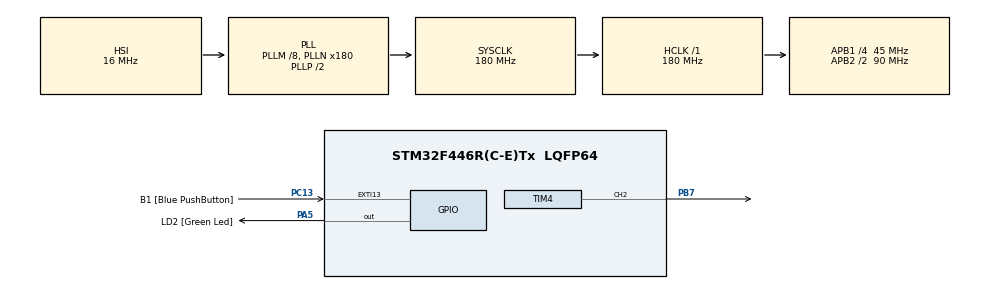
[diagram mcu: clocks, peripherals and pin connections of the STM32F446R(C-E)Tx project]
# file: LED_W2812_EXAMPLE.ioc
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Dma.Request0=TIM4_CH2
Dma.TIM4_CH2.0.Direction=DMA_MEMORY_TO_PERIPH
Dma.TIM4_CH2.0.FIFOMode=DMA_FIFOMODE_DISABLE
Dma.TIM4_CH2.0.Instance=DMA1_Stream3
Dma.TIM4_CH2.0.MemDataAlignment=DMA_MDATAALIGN_HALFWORD
Dma.TIM4_CH2.0.MemInc=DMA_MINC_ENABLE
Dma.TIM4_CH2.0.Mode=DMA_CIRCULAR
Dma.TIM4_CH2.0.PeriphDataAlignment=DMA_PDATAALIGN_HALFWORD
Dma.TIM4_CH2.0.PeriphInc=DMA_PINC_DISABLE
Dma.TIM4_CH2.0.Priority=DMA_PRIORITY_LOW
Mcu.Family=STM32F4
Mcu.Name=STM32F446R(C-E)Tx
Mcu.Package=LQFP64
NVIC.DMA1_Stream3_IRQn=true\:0\:0\:false\:false\:true\:false\:true\:true
NVIC.PriorityGroup=NVIC_PRIORITYGROUP_0
PA13.GPIO_Label=TMS
PA13.Signal=SYS_JTMS-SWDIO
PA14.GPIO_Label=TCK
PA14.Signal=SYS_JTCK-SWCLK
PA2.GPIO_Label=USART_TX
PA2.Signal=USART2_TX
PA3.GPIO_Label=USART_RX
PA3.Signal=USART2_RX
PA5.GPIO_Label=LD2 [Green Led]
PA5.Signal=GPIO_Output
PB3.GPIO_Label=SWO
PB3.Signal=SYS_JTDO-SWO
PB7.Signal=S_TIM4_CH2
PC13.GPIO_Label=B1 [Blue PushButton]
PC13.GPIO_ModeDefaultEXTI=GPIO_MODE_IT_FALLING
PC13.Signal=GPXTI13
PC14-OSC32_IN.Signal=RCC_OSC32_IN
PC15-OSC32_OUT.Signal=RCC_OSC32_OUT
PH0-OSC_IN.Signal=RCC_OSC_IN
PH1-OSC_OUT.Signal=RCC_OSC_OUT
ProjectManager.HeapSize=0x200
ProjectManager.StackSize=0x400
ProjectManager.TargetToolchain=STM32CubeIDE
RCC.AHBFreq_Value=180000000
RCC.APB1CLKDivider=RCC_HCLK_DIV4
RCC.APB1Freq_Value=45000000
RCC.APB1TimFreq_Value=90000000
RCC.APB2CLKDivider=RCC_HCLK_DIV2
RCC.APB2Freq_Value=90000000
RCC.APB2TimFreq_Value=180000000
RCC.CortexFreq_Value=180000000
RCC.FLatency-AdvancedSettings=FLASH_LATENCY_5
RCC.HCLKFreq_Value=180000000
RCC.HSE_VALUE=8000000
RCC.HSI_VALUE=16000000
RCC.LSE_VALUE=32768
RCC.PLLM=8
RCC.PLLN=180
RCC.SYSCLKFreq_VALUE=180000000
RCC.SYSCLKSource=RCC_SYSCLKSOURCE_PLLCLK
RCC.USBFreq_Value=180000000
RCC.VCOOutputFreq_Value=360000000
SH.S_TIM4_CH2.0=TIM4_CH2,PWM Generation2 CH2
TIM4.Channel-PWM\ Generation2\ CH2=TIM_CHANNEL_2
TIM4.OCFastMode_PWM-PWM\ Generation2\ CH2=TIM_OCFAST_DISABLE
TIM4.Period=112
VP_TIM4_VS_ClockSourceINT.Mode=Internal
board=NUCLEO-F446RE

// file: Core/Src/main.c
/* USER CODE BEGIN Header */
/**
 ******************************************************************************
 * @file           : main.c
 * @brief          : Main program body
 ******************************************************************************
 * @attention
 *
 * Copyright (c) 2022 STMicroelectronics.
 * All rights reserved.
 *
 * This software is licensed under terms that can be found in the LICENSE file
 * in the root directory of this software component.
 * If no LICENSE file comes with this software, it is provided AS-IS.
 *
 ******************************************************************************
 */
/* USER CODE END Header */
#include "main.h"
#include "dma.h"
#include "tim.h"
#include "gpio.h"

/* USER CODE BEGIN Includes */
#include "stdint.h"
#include "LED_W2812.h"
/* USER CODE END Includes */

/* USER CODE BEGIN PM */
#define LED_NUMBER 24
/* USER CODE END PM */

void SystemClock_Config(void);

/* USER CODE BEGIN 0 */
#define PUSH_BUTTON	HAL_GPIO_ReadPin(B1_GPIO_Port, B1_Pin)
/* USER CODE END 0 */

int MODE = 0;
int main(void)
{

	/* MCU Configuration--------------------------------------------------------*/

	/* Reset of all peripherals, Initializes the Flash interface and the Systick. */
	HAL_Init();

	/* Configure the system clock */
	SystemClock_Config();

	/* Initialize all configured peripherals */
	MX_GPIO_Init();
	MX_DMA_Init();
	MX_TIM4_Init();

	/* Infinite loop */
	/* USER CODE BEGIN WHILE */
	LED_init(&htim4, TIM_CHANNEL_2, LED_NUMBER);
	LED_setPeriode(10);
	LED_setColorAll(255, 255, 0, 0);

	while (1)
	{
		/* USER CODE END WHILE */

		/* USER CODE BEGIN 3 */
		LED_loop();

		HAL_GPIO_WritePin(LD2_GPIO_Port, LD2_Pin, PUSH_BUTTON);
		if (!PUSH_BUTTON)
		{
			while (!PUSH_BUTTON) HAL_Delay(10);
			MODE = (MODE + 1) % 6;
		}

		switch (MODE)
		{
			case 0: LED_setMode(LED_MODE_OFF); break;
			case 1: LED_setMode(LED_MODE_STATIC); break;
			case 2: LED_setMode(LED_MODE_BLINKING); break;
			case 3: LED_setMode(LED_MODE_BREATHING); break;
			case 4: LED_setMode(LED_MODE_RAINBOW1); break;
			case 5: LED_setMode(LED_MODE_RAINBOW1); break;
		}
	}
	/* USER CODE END 3 */
}

void SystemClock_Config(void)
{
	RCC_OscInitTypeDef RCC_OscInitStruct =
	{ 0 };
	RCC_ClkInitTypeDef RCC_ClkInitStruct =
	{ 0 };

	/** Configure the main internal regulator output voltage
	 */
	__HAL_RCC_PWR_CLK_ENABLE();
	__HAL_PWR_VOLTAGESCALING_CONFIG(PWR_REGULATOR_VOLTAGE_SCALE1);

	/** Initializes the RCC Oscillators according to the specified parameters
	 * in the RCC_OscInitTypeDef structure.
	 */
	RCC_OscInitStruct.OscillatorType = RCC_OSCILLATORTYPE_HSI;
	RCC_OscInitStruct.HSIState = RCC_HSI_ON;
	RCC_OscInitStruct.HSICalibrationValue = RCC_HSICALIBRATION_DEFAULT;
	RCC_OscInitStruct.PLL.PLLState = RCC_PLL_ON;
	RCC_OscInitStruct.PLL.PLLSource = RCC_PLLSOURCE_HSI;
	RCC_OscInitStruct.PLL.PLLM = 8;
	RCC_OscInitStruct.PLL.PLLN = 180;
	RCC_OscInitStruct.PLL.PLLP = RCC_PLLP_DIV2;
	RCC_OscInitStruct.PLL.PLLQ = 2;
	RCC_OscInitStruct.PLL.PLLR = 2;
	if (HAL_RCC_OscConfig(&RCC_OscInitStruct) != HAL_OK)
	{
		Error_Handler();
	}

	/** Activate the Over-Drive mode
	 */
	if (HAL_PWREx_EnableOverDrive() != HAL_OK)
	{
		Error_Handler();
	}

	/** Initializes the CPU, AHB and APB buses clocks
	 */
	RCC_ClkInitStruct.ClockType = RCC_CLOCKTYPE_HCLK | RCC_CLOCKTYPE_SYSCLK
			| RCC_CLOCKTYPE_PCLK1 | RCC_CLOCKTYPE_PCLK2;
	RCC_ClkInitStruct.SYSCLKSource = RCC_SYSCLKSOURCE_PLLCLK;
	RCC_ClkInitStruct.AHBCLKDivider = RCC_SYSCLK_DIV1;
	RCC_ClkInitStruct.APB1CLKDivider = RCC_HCLK_DIV4;
	RCC_ClkInitStruct.APB2CLKDivider = RCC_HCLK_DIV2;

	if (HAL_RCC_ClockConfig(&RCC_ClkInitStruct, FLASH_LATENCY_5) != HAL_OK)
	{
		Error_Handler();
	}
}

/* USER CODE BEGIN 4 */
//void HAL_TIM_PWM_PulseFinishedCallback(TIM_HandleTypeDef *htim)
//{
//	if(htim == &htim4)
//	{
//		HAL_TIM_PWM_Stop_DMA(&htim4, TIM_CHANNEL_2);
//	}
//}
/* USER CODE END 4 */

void Error_Handler(void)
{
	__disable_irq();
	while (1)
	{
	}
}
